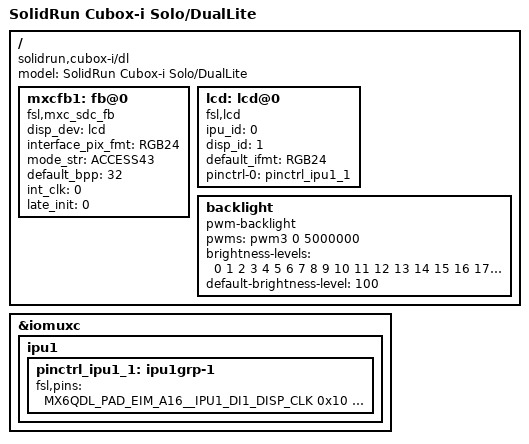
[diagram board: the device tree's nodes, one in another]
/*
 * Copyright (C) 2014 Russell King
 *
 * This file is dual-licensed: you can use it either under the terms
 * of the GPL or the X11 license, at your option. Note that this dual
 * licensing only applies to this file, and not this project as a
 * whole.
 *
 *  a) This file is free software; you can redistribute it and/or
 *     modify it under the terms of the GNU General Public License as
 *     published by the Free Software Foundation; either version 2 of the
 *     License.
 *
 *     This file is distributed in the hope that it will be useful
 *     but WITHOUT ANY WARRANTY; without even the implied warranty of
 *     MERCHANTABILITY or FITNESS FOR A PARTICULAR PURPOSE.  See the
 *     GNU General Public License for more details.
 *
 * Or, alternatively
 *
 *  b) Permission is hereby granted, free of charge, to any person
 *     obtaining a copy of this software and associated documentation
 *     files (the "Software"), to deal in the Software without
 *     restriction, including without limitation the rights to use
 *     copy, modify, merge, publish, distribute, sublicense, and/or
 *     sell copies of the Software, and to permit persons to whom the
 *     Software is furnished to do so, subject to the following
 *     conditions:
 *
 *     The above copyright notice and this permission notice shall be
 *     included in all copies or substantial portions of the Software.
 *
 *     THE SOFTWARE IS PROVIDED , WITHOUT WARRANTY OF ANY KIND
 *     EXPRESS OR IMPLIED, INCLUDING BUT NOT LIMITED TO THE WARRANTIES
 *     OF MERCHANTABILITY, FITNESS FOR A PARTICULAR PURPOSE AND
 *     NONINFRINGEMENT. IN NO EVENT SHALL THE AUTHORS OR COPYRIGHT
 *     HOLDERS BE LIABLE FOR ANY CLAIM, DAMAGES OR OTHER LIABILITY
 *     WHETHER IN AN ACTION OF CONTRACT, TORT OR OTHERWISE, ARISING
 *     FROM, OUT OF OR IN CONNECTION WITH THE SOFTWARE OR THE USE OR
 *     OTHER DEALINGS IN THE SOFTWARE.
 */
/dts-v1/;

#include "imx6dl.dtsi"
#include "imx6qdl-cubox-i.dtsi"

/ {
	model = "SolidRun Cubox-i Solo/DualLite";
	compatible = "solidrun,cubox-i/dl", "fsl,imx6dl";

	mxcfb1: fb@0 {
		compatible = "fsl,mxc_sdc_fb";
		disp_dev = "lcd";
		interface_pix_fmt = "RGB24";
		mode_str ="ACCESS43";
		default_bpp = <32>;
		int_clk = <0>;
		late_init = <0>;
		status = "okay";
	};

	lcd: lcd@0 {
		compatible = "fsl,lcd";
		ipu_id = <0>;
		disp_id = <1>;
		default_ifmt = "RGB24";
		pinctrl-names = "default";
		pinctrl-0 = <&pinctrl_ipu1_1>;
		status = "okay";
	};
	
	backlight {
                compatible = "pwm-backlight";
                pwms = <&pwm3 0 5000000>;
                brightness-levels = <0  1  2  3  4  5  6  7  8  9

             10 11 12 13 14 15 16 17 18 19

             20 21 22 23 24 25 26 27 28 29

             30 31 32 33 34 35 36 37 38 39

             40 41 42 43 44 45 46 47 48 49

             50 51 52 53 54 55 56 57 58 59

             60 61 62 63 64 65 66 67 68 69

             70 71 72 73 74 75 76 77 78 79

             80 81 82 83 84 85 86 87 88 89

             90 91 92 93 94 95 96 97 98 99

            100>;
                default-brightness-level = <100>;
        };

};
&iomuxc{
	ipu1 {
		pinctrl_ipu1_1: ipu1grp-1 {
			fsl,pins = <
				MX6QDL_PAD_EIM_A16__IPU1_DI1_DISP_CLK      0x10
				MX6QDL_PAD_EIM_DA10__IPU1_DI1_PIN15        0x10
				MX6QDL_PAD_EIM_DA11__IPU1_DI1_PIN02        0x10
				MX6QDL_PAD_EIM_DA12__IPU1_DI1_PIN03        0x10
				MX6QDL_PAD_EIM_DA14__IPU1_DI1_D1_CS        0x10
//				MX6QDL_PAD_EIM_DA13__IPU1_DI1_D0_CS        0x10

				MX6QDL_PAD_EIM_DA9__IPU1_DISP1_DATA00  	   0x10
				MX6QDL_PAD_EIM_DA8__IPU1_DISP1_DATA01      0x10
				MX6QDL_PAD_EIM_DA7__IPU1_DISP1_DATA02      0x10
				MX6QDL_PAD_EIM_DA6__IPU1_DISP1_DATA03      0x10
				MX6QDL_PAD_EIM_DA5__IPU1_DISP1_DATA04      0x10
				MX6QDL_PAD_EIM_DA4__IPU1_DISP1_DATA05      0x10
				MX6QDL_PAD_EIM_DA3__IPU1_DISP1_DATA06      0x10
				MX6QDL_PAD_EIM_DA2__IPU1_DISP1_DATA07      0x10

				MX6QDL_PAD_EIM_DA1__IPU1_DISP1_DATA08      0x10
				MX6QDL_PAD_EIM_DA0__IPU1_DISP1_DATA09      0x10
				MX6QDL_PAD_EIM_EB1__IPU1_DISP1_DATA10      0x10
				MX6QDL_PAD_EIM_EB0__IPU1_DISP1_DATA11      0x10
				MX6QDL_PAD_EIM_A17__IPU1_DISP1_DATA12      0x10
				MX6QDL_PAD_EIM_A18__IPU1_DISP1_DATA13      0x10
				MX6QDL_PAD_EIM_A19__IPU1_DISP1_DATA14      0x10
				MX6QDL_PAD_EIM_A20__IPU1_DISP1_DATA15      0x10

				MX6QDL_PAD_EIM_A21__IPU1_DISP1_DATA16      0x10
				MX6QDL_PAD_EIM_A22__IPU1_DISP1_DATA17      0x10
				MX6QDL_PAD_EIM_A23__IPU1_DISP1_DATA18      0x10
				MX6QDL_PAD_EIM_A24__IPU1_DISP1_DATA19      0x10
				MX6QDL_PAD_EIM_D31__IPU1_DISP1_DATA20      0x10
				MX6QDL_PAD_EIM_D30__IPU1_DISP1_DATA21      0x10
				MX6QDL_PAD_EIM_D26__IPU1_DISP1_DATA22      0x10
				MX6QDL_PAD_EIM_D27__IPU1_DISP1_DATA23      0x10
				>;
			};
		};
	};
